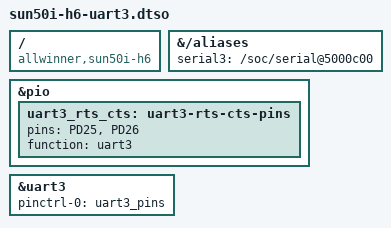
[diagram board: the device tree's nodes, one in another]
/dts-v1/;
/plugin/;

/ {
	compatible = "allwinner,sun50i-h6";

	fragment@0 {
		target-path = "/aliases";
		__overlay__ {
			serial3 = "/soc/serial@5000c00";
		};
	};

	fragment@1 {
		target = <&pio>;
		__overlay__ {
			uart3_rts_cts: uart3-rts-cts-pins {
				pins = "PD25", "PD26";
				function = "uart3";
			};
		};
	};

	fragment@2 {
		target = <&uart3>;
		 __overlay__ {
			pinctrl-names = "default";
			pinctrl-0 = <&uart3_pins>;
			status = "okay";
		};
	};
};
